# bcm2711_lpa register map
Vendor: BROADCOM; Series: BCM2711; File version: A
CPU: CA72 r0p0, little endian, MPU, FPU, 2 interrupt priority bits
Registers are 32-bit, read-write, reset 0x0 unless marked. A register's access mark holds for its fields unless they carry their own. Offsets are from the block's base; [hi:lo] are bit positions; {n}, {i} and the like mark numbered series.

## SYSTMR — Broadcom System Timer
Base 0xFE003000
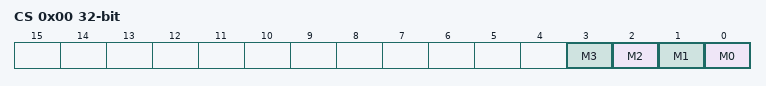
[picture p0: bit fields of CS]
0x00 CS — Control / Status
  [n] M{n} write-1-clears (n=0..3) — System timer match {n}
0x04 CLO ro — Lower 32 bits for the free running counter
0x08 CHI ro — Higher 32 bits for the free running counter
{0xC+4i} C{i} (i=0..3) — Compare channel {i}

## UART0 — ARM Prime Cell PL011
Base 0xFE201000
Same registers: UART2 0xFE201400, UART3 0xFE201600, UART4 0xFE201800, UART5 0xFE201A00
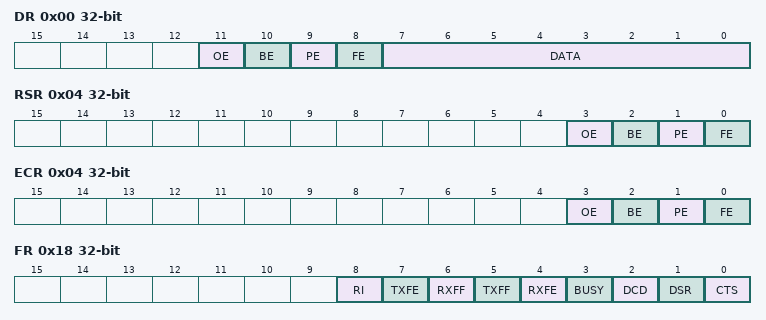
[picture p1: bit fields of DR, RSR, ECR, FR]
0x00 DR — Data Register
  [11] OE, [10] BE, [9] PE, [8] FE, [7:0] DATA
0x04 RSR ro — Receive Status Register
  [3] OE, [2] BE, [1] PE, [0] FE
0x04 ECR wo — Error Clear Register
  [3] OE, [2] BE, [1] PE, [0] FE
0x18 FR — Flag Register
  [8] RI, [7] TXFE, [6] RXFF, [5] TXFF, [4] RXFE, [3] BUSY, [2] DCD, [1] DSR, [0] CTS
0x24 IBRD — Integer Baud Rate Register
  [15:0] BAUDDIVINT
0x28 FBRD — Fractional Baud Rate Register
  [5:0] BAUDDIVFRAC
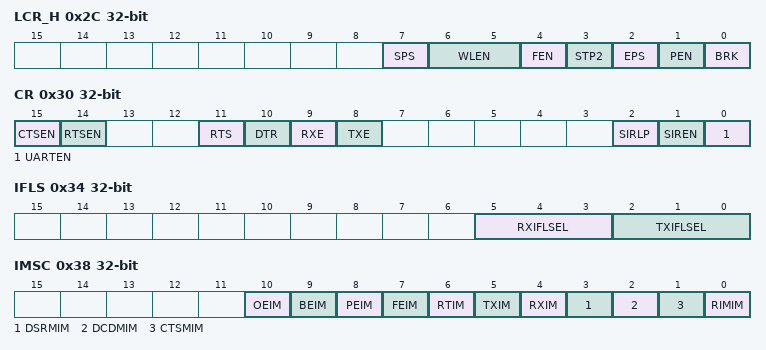
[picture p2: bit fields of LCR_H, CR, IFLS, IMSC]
0x2C LCR_H — Line Control Register
  [7] SPS, [6:5] WLEN, [4] FEN, [3] STP2, [2] EPS, [1] PEN, [0] BRK
0x30 CR — Control Register
  [15] CTSEN, [14] RTSEN, [11] RTS, [10] DTR, [9] RXE, [8] TXE, [2] SIRLP, [1] SIREN, [0] UARTEN
0x34 IFLS — Interrupt FIFO Level Select Register
  [5:3] RXIFLSEL, [2:0] TXIFLSEL
0x38 IMSC — Interrupt Mask set_Clear Register
  [10] OEIM, [9] BEIM, [8] PEIM, [7] FEIM, [6] RTIM, [5] TXIM, [4] RXIM, [3] DSRMIM, [2] DCDMIM, [1] CTSMIM, [0] RIMIM
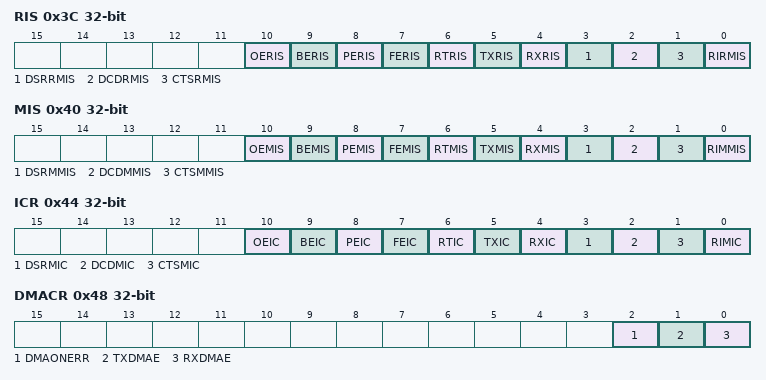
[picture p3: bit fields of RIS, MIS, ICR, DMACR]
0x3C RIS ro — Raw Interrupt Status Register
  [10] OERIS, [9] BERIS, [8] PERIS, [7] FERIS, [6] RTRIS, [5] TXRIS, [4] RXRIS, [3] DSRRMIS, [2] DCDRMIS, [1] CTSRMIS, [0] RIRMIS
0x40 MIS ro — Masked Interrupt Status Register
  [10] OEMIS, [9] BEMIS, [8] PEMIS, [7] FEMIS, [6] RTMIS, [5] TXMIS, [4] RXMIS, [3] DSRMMIS, [2] DCDMMIS, [1] CTSMMIS, [0] RIMMIS
0x44 ICR wo — Interrupt Clear Register
  [10] OEIC, [9] BEIC, [8] PEIC, [7] FEIC, [6] RTIC, [5] TXIC, [4] RXIC, [3] DSRMIC, [2] DCDMIC, [1] CTSMIC, [0] RIMIC
0x48 DMACR — DMA Control Register
  [2] DMAONERR, [1] TXDMAE, [0] RXDMAE

## SPI0 — Broadcom SPI Controller
Base 0xFE204000
Same registers: SPI3 0xFE204600, SPI4 0xFE204800, SPI5 0xFE204A00, SPI6 0xFE204C00
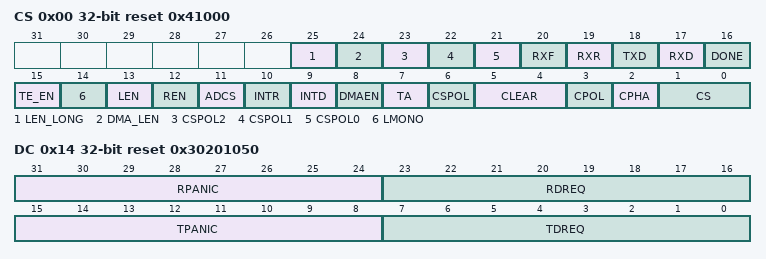
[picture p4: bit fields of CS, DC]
0x00 CS reset 0x41000 — Control and Status
  [25] LEN_LONG — Enable long data word in LoSSI mode
  [24] DMA_LEN — Enable DMA in LoSSI mode
  [23] CSPOL2 — Chip select 2 polarity
  [22] CSPOL1 — Chip select 1 polarity
  [21] CSPOL0 — Chip select 0 polarity
  [20] RXF ro — RX FIFO full
  [19] RXR ro — RX FIFO has data to be read
  [18] TXD ro — TX FIFO can accept data
  [17] RXD ro — RX FIFO contains data
  [16] DONE ro — Transfer is done
  [15] TE_EN
  [14] LMONO
  [13] LEN — LoSSI enable
  [12] REN — Read enable
  [11] ADCS — Automatically deassert chip select
  [10] INTR — Interrupt on RX
  [9] INTD — Interrupt on done
  [8] DMAEN — Enable DMA
  [7] TA — Transfer active
  [6] CSPOL — Chip select polarity
  [5:4] CLEAR — Clear the FIFO(s)
    1=TX; 2=RX; 3=BOTH
  [3] CPOL — Clock polarity
  [2] CPHA — Clock phase
  [1:0] CS — Chip select
0x04 FIFO — FIFO access
  [31:0] DATA
0x08 CLK — Clock divider
  [15:0] CDIV
0x0C DLEN — Data length
  [15:0] DLEN
0x10 LTOH reset 0x1 — LoSSI output hold delay
  [3:0] TOH — Output hold delay
0x14 DC reset 0x30201050
  [31:24] RPANIC — DMA read panic threshold
  [23:16] RDREQ — DMA read request threshold
  [15:8] TPANIC — DMA write panic threshold
  [7:0] TDREQ — DMA Write request threshold

## PACTL — Interrupt status of new peripherals
Base 0xFE204E00
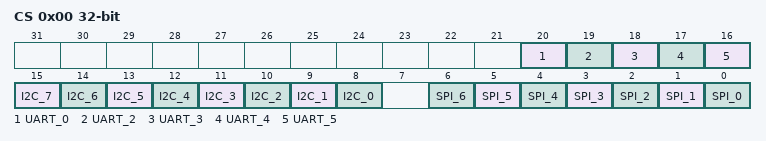
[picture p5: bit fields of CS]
0x00 CS — Interrupt status
  [20] UART_0 — UART0 interrupt active
  [21-n] UART_{n} (n=2..5) — UART{n} interrupt active
  [n+8] I2C_{n} (n=0..7) — I2C{n} interrupt active
  [n] SPI_{n} (n=0..6) — SPI{n} interrupt active
